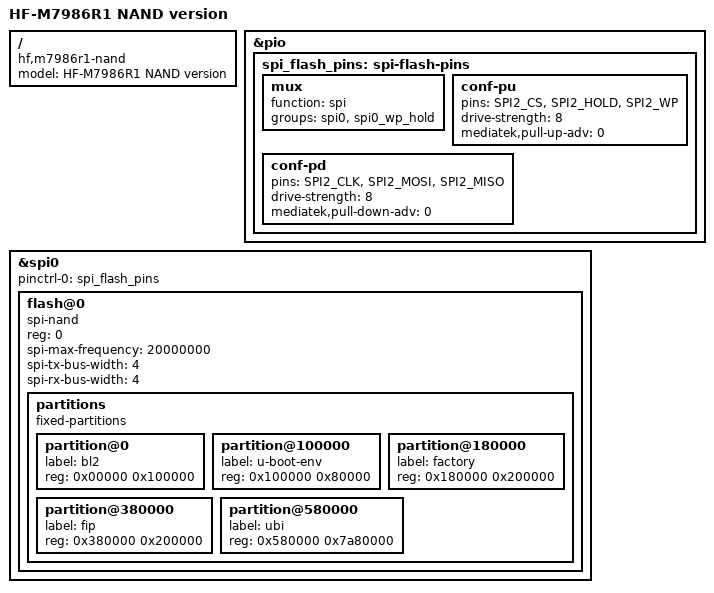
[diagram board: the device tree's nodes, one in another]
// SPDX-License-Identifier: GPL-2.0-or-later OR MIT

/dts-v1/;
#include "mt7986a-hf-m7986r1.dtsi"

/ {
	model = "HF-M7986R1 NAND version";
	compatible = "hf,m7986r1-nand", "mediatek,mt7986a";
};

&pio {
	spi_flash_pins: spi-flash-pins {
		mux {
			function = "spi";
			groups = "spi0", "spi0_wp_hold";
		};
		conf-pu {
			pins = "SPI2_CS", "SPI2_HOLD", "SPI2_WP";
			drive-strength = <8>;
			mediatek,pull-up-adv = <0>;
		};
		conf-pd {
			pins = "SPI2_CLK", "SPI2_MOSI", "SPI2_MISO";
			drive-strength = <8>;
			mediatek,pull-down-adv = <0>;
		};
	};
};

&spi0 {
	pinctrl-names = "default";
	pinctrl-0 = <&spi_flash_pins>;
	status = "okay";

	flash@0 {
		compatible = "spi-nand";
		#address-cells = <1>;
		#size-cells = <1>;
		reg = <0>;

		spi-max-frequency = <20000000>;
		spi-tx-bus-width = <4>;
		spi-rx-bus-width = <4>;

		partitions {
			compatible = "fixed-partitions";
			#address-cells = <1>;
			#size-cells = <1>;

			partition@0 {
				label = "bl2";
				reg = <0x00000 0x100000>;
			};

			partition@100000 {
				label = "u-boot-env";
				reg = <0x100000 0x80000>;
			};

			partition@180000 {
				label = "factory";
				reg = <0x180000 0x200000>;
			};

			partition@380000 {
				label = "fip";
				reg = <0x380000 0x200000>;
			};

			partition@580000 {
				label = "ubi";
				reg = <0x580000 0x7a80000>;
			};
		};
	};
};
